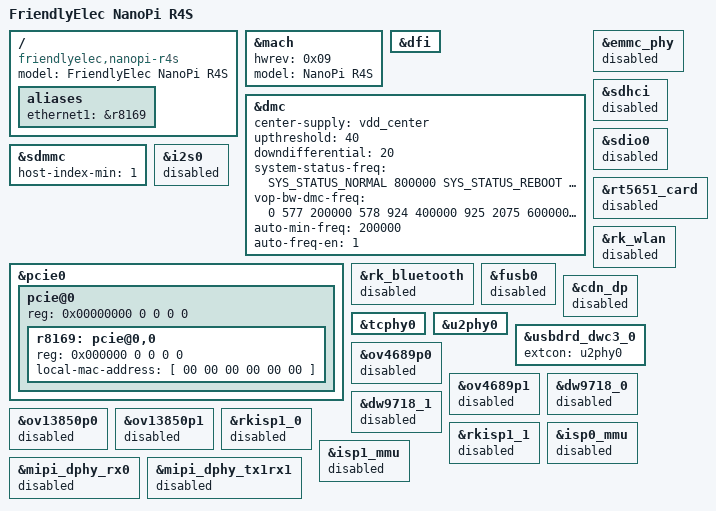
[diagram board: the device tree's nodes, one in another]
// SPDX-License-Identifier: (GPL-2.0+ OR MIT)
/*
 * Copyright (c) 2020 FriendlyElec Computer Tech. Co., Ltd.
 * (http://www.friendlyarm.com)
 */

/dts-v1/;
#include "rk3399-nanopi4-common.dtsi"

/ {
	model = "FriendlyElec NanoPi R4S";
	compatible = "friendlyelec,nanopi-r4s", "rockchip,rk3399";

	aliases {
		ethernet1 = &r8169;
	};
};

&mach {
	hwrev = <0x09>;
	model = "NanoPi R4S";
};

&dfi {
	status = "okay";
};

&dmc {
	status = "okay";
	center-supply = <&vdd_center>;
	upthreshold = <40>;
	downdifferential = <20>;
	system-status-freq = <
		/*system status         freq(KHz)*/
		SYS_STATUS_NORMAL       800000
		SYS_STATUS_REBOOT       528000
		SYS_STATUS_SUSPEND      200000
		SYS_STATUS_VIDEO_1080P  200000
		SYS_STATUS_VIDEO_4K     600000
		SYS_STATUS_VIDEO_4K_10B 800000
		SYS_STATUS_PERFORMANCE  800000
		SYS_STATUS_BOOST        600000
		SYS_STATUS_DUALVIEW     600000
		SYS_STATUS_ISP          600000
	>;
	vop-bw-dmc-freq = <
	/* min_bw(MB/s) max_bw(MB/s) freq(KHz) */
		0       577      200000
		578     924      400000
		925     2075     600000
		2076    99999    800000
	>;
	auto-min-freq = <200000>;
	auto-freq-en = <1>;
};

&emmc_phy {
	status = "disabled";
};

&sdhci {
	status = "disabled";
};

&sdio0 {
	status = "disabled";
};

&sdmmc {
	host-index-min = <1>;
};

&i2s0 {
	status = "disabled";
};

&pcie0 {
	pcie@0 {
		reg = <0x00000000 0 0 0 0>;
		#address-cells = <3>;
		#size-cells = <2>;

		r8169: pcie@0,0 {
			reg = <0x000000 0 0 0 0>;
			local-mac-address = [ 00 00 00 00 00 00 ];
		};
	};
};

&rt5651_card {
	status = "disabled";
};

&rk_bluetooth {
	status = "disabled";
};

&rk_wlan {
	status = "disabled";
};

&fusb0 {
	status = "disabled";
};

&cdn_dp {
	/delete-property/ extcon;
	status = "disabled";
};

&tcphy0 {
	/delete-property/ extcon;
};

&u2phy0 {
	/delete-property/ extcon;
};

&usbdrd_dwc3_0 {
	/delete-property/ extcon;
	extcon = <&u2phy0>;
};

&ov4689p0 {
	status = "disabled";
};

&ov4689p1 {
	status = "disabled";
};

&dw9718_0 {
	status = "disabled";
};

&dw9718_1 {
	status = "disabled";
};

&ov13850p0 {
	status = "disabled";
};

&ov13850p1 {
	status = "disabled";
};

&rkisp1_0 {
	status = "disabled";
};

&rkisp1_1 {
	status = "disabled";
};

&isp0_mmu {
	status = "disabled";
};

&isp1_mmu {
	status = "disabled";
};

&mipi_dphy_rx0 {
	status = "disabled";
};

&mipi_dphy_tx1rx1 {
	status = "disabled";
};
